# ESP32-C5 register map
Vendor: ESPRESSIF SYSTEMS (SHANGHAI) CO., LTD.; Series: ESP32 C-Series; File version: 1
CPU: RV32IMAC r0p0, little endian, no MPU, no FPU, 0 interrupt priority bits
Address unit: 32 bits
Registers are 32-bit, read-write, reset 0x0 unless marked. A register's access mark holds for its fields unless they carry their own. Offsets are from the block's base; [hi:lo] are bit positions; lines under a group give offsets from that group; {n}, {i} and the like mark numbered series.

## SHA — SHA (Secure Hash Algorithm) Accelerator
Base 0x60089000
0x00 MODE — Configures SHA algorithm
  [2:0] MODE — Configures the SHA algorithm. \\ 0: SHA-1\\ 1: SHA-224\\ 2: SHA-256\\
0x04 T_STRING — SHA 512/t configuration register 0.
  [31:0] T_STRING — Sha t_string (used if and only if mode == SHA_512/t).
0x08 T_LENGTH — SHA 512/t configuration register 1.
  [5:0] T_LENGTH — Sha t_length (used if and only if mode == SHA_512/t).
0x0C DMA_BLOCK_NUM — Block number register (only effective for DMA-SHA)
  [5:0] DMA_BLOCK_NUM — Configures the DMA-SHA block number.
0x10 START wo — Starts the SHA accelerator for Typical SHA operation
  [0] START — Write 1 to start Typical SHA calculation.
0x14 CONTINUE wo — Continues SHA operation (only effective in Typical SHA mode)
  [0] CONTINUE — Write 1 to continue Typical SHA calculation.
0x18 BUSY ro — Represents if SHA Accelerator is busy or not
  [0] STATE — Represents the states of SHA accelerator. \\ 0: idle\\ 1: busy\\
0x1C DMA_START wo — Starts the SHA accelerator for DMA-SHA operation
  [0] DMA_START — Write 1 to start DMA-SHA calculation.
0x20 DMA_CONTINUE wo — Continues SHA operation (only effective in DMA-SHA mode)
  [0] DMA_CONTINUE — Write 1 to continue DMA-SHA calculation.
0x24 CLEAR_IRQ wo — DMA-SHA interrupt clear register
  [0] CLEAR_INTERRUPT — Write 1 to clear DMA-SHA interrupt.
0x28 IRQ_ENA — DMA-SHA interrupt enable register
  [0] INTERRUPT_ENA — Write 1 to enable DMA-SHA interrupt.
0x2C DATE — Version control register
{0x40+4i} H_MEM[{i}] (i=0..7) access not given — Sha H memory which contains intermediate hash or finial hash.
{0x80+4i} M_MEM[{i}] (i=0..15) access not given — Sha M memory which contains message.
0x800 _3_MODE — Initial configuration register 0.
  [2:0] _3_MODE — Sha3 mode
0x804 _3_CLEAN_M wo — Initial configuration register 1.
  [0] _3_CLEAN_M — Clean Message.
0x80C _3_DMA_BLOCK_NUM — DMA configuration register 0.
  [5:0] _3_DMA_BLOCK_NUM — DMA-SHA3 block number.
0x810 _3_START wo — Typical SHA3 configuration register 0.
  [0] _3_START — Start typical sha3.
0x814 _3_CONTINUE wo — Typical SHA3 configuration register 1.
  [0] _3_CONTINUE — Continue typical sha3.
0x818 _3_BUSY ro — Busy register.
  [0] _3_BUSY — Sha3 busy state. 1'b0: idle. 1'b1: busy.
0x81C _3_DMA_START wo — DMA configuration register 1.
  [0] _3_DMA_START — Start dma-sha3.
0x820 _3_DMA_CONTINUE wo — DMA configuration register 2.
  [0] _3_DMA_CONTINUE — Continue dma-sha3.
0x824 _3_CLEAR_INT wo — Interrupt clear register.
  [0] _3_CLEAR_INT — Clear sha3 interrupt.
0x828 _3_INT_ENA — Interrupt enable register.
  [0] _3_INT_ENA — Sha3 interrupt enable register. 1'b0: disable(default). 1'b1:enable
0x82C _3_SHAKE_LENGTH wo reset 0x32 — DMA configuration register 3.
  [10:0] _3_SHAKE_LENGTH — SHAKE output hash word length
{0x900+i} _3_M_OUT_MEM[{i}] (i=0..199) 8-bit access not given — Sha3 hash reg which contains intermediate hash or finial hash.
{0xA00+i} _3_M_MEM[{i}] (i=0..199) 8-bit access not given — Sha3 message reg which contains message.

## SYSTIMER — System Timer
Base 0x6000A000
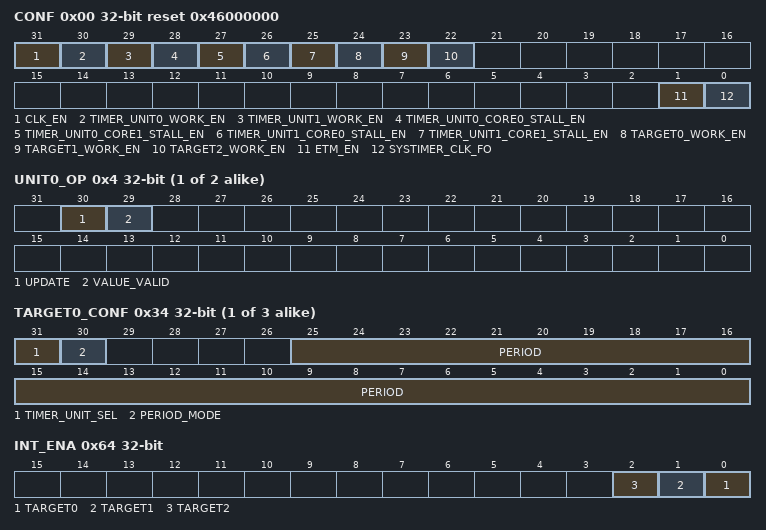
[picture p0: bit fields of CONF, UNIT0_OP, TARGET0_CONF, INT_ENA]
0x00 CONF reset 0x46000000 — Configure system timer clock
  [31] CLK_EN — register file clk gating
  [30] TIMER_UNIT0_WORK_EN — timer unit0 work enable
  [29] TIMER_UNIT1_WORK_EN — timer unit1 work enable
  [28] TIMER_UNIT0_CORE0_STALL_EN — If timer unit0 is stalled when core0 stalled
  [27] TIMER_UNIT0_CORE1_STALL_EN — If timer unit0 is stalled when core1 stalled
  [26] TIMER_UNIT1_CORE0_STALL_EN — If timer unit1 is stalled when core0 stalled
  [25] TIMER_UNIT1_CORE1_STALL_EN — If timer unit1 is stalled when core1 stalled
  [24] TARGET0_WORK_EN — target0 work enable
  [23] TARGET1_WORK_EN — target1 work enable
  [22] TARGET2_WORK_EN — target2 work enable
  [1] ETM_EN — enable systimer's etm task and event
  [0] SYSTIMER_CLK_FO — systimer clock force on
{0x4+4i} UNIT{i}_OP (i=0..1) access per field — system timer unit{i} value update register
  [30] UPDATE wo — update timer_unit0
  [29] VALUE_VALID ro — timer value is sync and valid
{0xC+8i} UNIT{i}LOAD (i=0..1) group — Cluster UNIT{i}LOAD, containing UNIT?_LOAD_HI, UNIT?_LOAD_LO
  0x00 HI — system timer unit0 value high load register
    [19:0] LOAD_HI — timer unit0 load high 20 bits
  0x04 LO — system timer unit0 value low load register
    [31:0] LOAD_LO — timer unit0 load low 32 bits
{0x1C+8i} TRGT{i} (i=0..2) group — Cluster TRGT{i}, containing TARGET?_HI, TARGET?_LO
  0x00 HI — system timer comp0 value high register
    [19:0] HI — timer taget0 high 20 bits
  0x04 LO — system timer comp0 value low register
    [31:0] LO — timer taget0 low 32 bits
{0x34+4i} TARGET{i}_CONF (i=0..2) — system timer comp{i} target mode register
  [31] TIMER_UNIT_SEL — select which unit to compare
  [30] PERIOD_MODE — Set target0 to period mode
  [25:0] PERIOD — target0 period
{0x40+8i} UNIT{i}_VALUE (i=0..1) group — Cluster UNIT{i}_VALUE, containing UNIT?_VALUE_HI, UNIT?_VALUE_LO
  0x00 HI ro — system timer unit0 value high register
    [19:0] VALUE_HI — timer read value high 20bits
  0x04 LO ro — system timer unit0 value low register
    [31:0] VALUE_LO — timer read value low 32bits
{0x50+4i} COMP{i}_LOAD (i=0..2) wo — system timer comp{i} conf sync register
  [0] LOAD — timer comp0 sync enable signal
{0x5C+4i} UNIT{i}_LOAD (i=0..1) wo — system timer unit{i} conf sync register
  [0] LOAD — timer unit0 sync enable signal
0x64 INT_ENA — systimer interrupt enable register
  [n] TARGET{n} (n=0..2) — interupt{n} enable
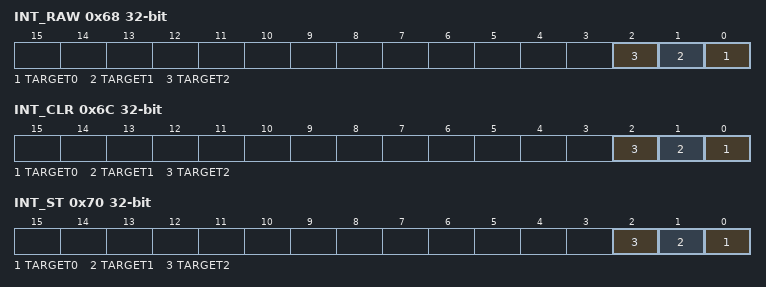
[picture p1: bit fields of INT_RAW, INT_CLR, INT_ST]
0x68 INT_RAW — systimer interrupt raw register
  [n] TARGET{n} (n=0..2) — interupt{n} raw
0x6C INT_CLR wo — systimer interrupt clear register
  [n] TARGET{n} (n=0..2) write-1-clears — interupt{n} clear
0x70 INT_ST ro — systimer interrupt status register
  [n] TARGET{n} (n=0..2) — interupt{n} status
{0x74+8i} REAL_TARGET{i} (i=0..2) group — Cluster REAL_TARGET{i}, containing REAL_TARGET?_LO, REAL_TARGET?_HI
  0x00 LO ro — system timer comp0 actual target value low register
    [31:0] LO_RO — actual target value value low 32bits
  0x04 HI ro — system timer comp0 actual target value high register
    [19:0] HI_RO — actual target value value high 20bits
0xFC DATE — system timer version control register

## TEE — TEE Peripheral
Base 0x60098000
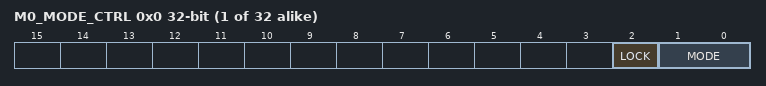
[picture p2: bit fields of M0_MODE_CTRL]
{0x0+4i} M{i}_MODE_CTRL (i=0..31) — TEE mode control register
  [2] LOCK — Set 1 to lock m0 tee configuration
  [1:0] MODE — Configures M%s security level mode.\\ 0: tee_mode \\ 1: ree_mode0 \\ 2: ree_mode1 \\ 3: ree_mode2 \\
    0=Tee (Tee mode); 1=Ree0 mode; 2=Ree1 mode; 3=Ree2 mode
0x80 CLOCK_GATE reset 0x1 — Clock gating register
  [0] CLK_EN — Configures whether to keep the clock always on.\\ 0: enable automatic clock gating \\ 1: keep the clock always on \\
0xFFC DATE — Version control register
